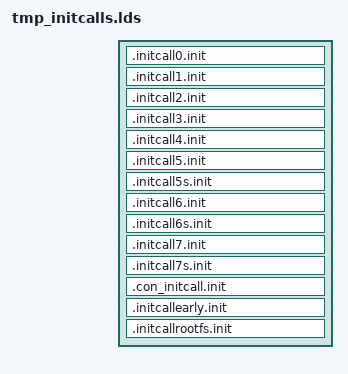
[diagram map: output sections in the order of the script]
SECTIONS {
	.initcall0.init : {
		*(.initcall0.init..kmod_shm__367_143_ipc_ns_init) ;
		*(.initcall0.init..kmod_min_addr__219_53_init_mmap_min_addr) ;
		*(.initcall0.init..kmod_pci__408_6605_pci_realloc_setup_params) ;
		*(.initcall0.init..kmod_net_namespace__576_1128_net_ns_init) ;
		*(.initcall0.init..kmod_inet_fragment__604_216_inet_frag_wq_init) ;
	}
	.initcall1.init : {
		*(.initcall1.init..kmod_e820__321_792_e820__register_nvs_regions) ;
		*(.initcall1.init..kmod_tsc__193_1028_cpufreq_register_tsc_scaling) ;
		*(.initcall1.init..kmod_reboot__355_516_reboot_init) ;
		*(.initcall1.init..kmod_apic__624_2779_init_lapic_sysfs) ;
		*(.initcall1.init..kmod_cpu__542_1454_alloc_frozen_cpus) ;
		*(.initcall1.init..kmod_cpu__544_1501_cpu_hotplug_pm_sync_init) ;
		*(.initcall1.init..kmod_workqueue__525_5640_wq_sysfs_init) ;
		*(.initcall1.init..kmod_ksysfs__238_269_ksysfs_init) ;
		*(.initcall1.init..kmod_cpufreq_schedutil__853_943_schedutil_gov_init) ;
		*(.initcall1.init..kmod_main__316_959_pm_init) ;
		*(.initcall1.init..kmod_hibernate__480_1268_pm_disk_init) ;
		*(.initcall1.init..kmod_swap__313_1613_swsusp_header_init) ;
		*(.initcall1.init..kmod_update__445_238_rcu_set_runtime_mode) ;
		*(.initcall1.init..kmod_jiffies__103_87_init_jiffies_clocksource) ;
		*(.initcall1.init..kmod_futex__327_4041_futex_init) ;
		*(.initcall1.init..kmod_cgroup__806_5785_cgroup_wq_init) ;
		*(.initcall1.init..kmod_cgroup_v1__351_1246_cgroup1_wq_init) ;
		*(.initcall1.init..kmod_trace_kprobe__313_1918_init_kprobe_trace_early) ;
		*(.initcall1.init..kmod_memory__426_157_init_zero_pfn) ;
		*(.initcall1.init..kmod_fsnotify__264_572_fsnotify_init) ;
		*(.initcall1.init..kmod_locks__467_3028_filelock_init) ;
		*(.initcall1.init..kmod_binfmt_misc__269_833_init_misc_binfmt) ;
		*(.initcall1.init..kmod_binfmt_script__197_156_init_script_binfmt) ;
		*(.initcall1.init..kmod_binfmt_elf__276_2311_init_elf_binfmt) ;
		*(.initcall1.init..kmod_compat_binfmt_elf__278_2311_init_compat_elf_binfmt) ;
		*(.initcall1.init..kmod_debugfs__266_844_debugfs_init) ;
		*(.initcall1.init..kmod_tracefs__244_550_tracefs_init) ;
		*(.initcall1.init..kmod_random32__417_489_prandom_init_early) ;
		*(.initcall1.init..kmod_iommu__392_2663_iommu_init) ;
		*(.initcall1.init..kmod_component__206_124_component_debug_init) ;
		*(.initcall1.init..kmod_trace__332_292_early_resume_init) ;
		*(.initcall1.init..kmod_cpufreq__559_2900_cpufreq_core_init) ;
		*(.initcall1.init..kmod_cpufreq_performance__180_44_cpufreq_gov_performance_init) ;
		*(.initcall1.init..kmod_cpufreq_userspace__183_141_cpufreq_gov_userspace_init) ;
		*(.initcall1.init..kmod_cpufreq_ondemand__195_477_CPU_FREQ_GOV_ONDEMAND_init) ;
		*(.initcall1.init..kmod_cpuidle__504_779_cpuidle_init) ;
		*(.initcall1.init..kmod_socket__637_3082_sock_init) ;
		*(.initcall1.init..kmod_sock__787_3384_net_inuse_init) ;
		*(.initcall1.init..kmod_net_namespace__545_393_net_defaults_init) ;
		*(.initcall1.init..kmod_flow_dissector__651_1806_init_default_flow_dissectors) ;
		*(.initcall1.init..kmod_netpoll__656_808_netpoll_init) ;
		*(.initcall1.init..kmod_af_netlink__647_2901_netlink_proto_init) ;
		*(.initcall1.init..kmod_genetlink__550_1411_genl_init) ;
		*(.initcall1.init..kmod_cpu__398_401_bsp_pm_check_init) ;
	}
	.initcall2.init : {
		*(.initcall2.init..kmod_irqdesc__172_331_irq_sysfs_init) ;
		*(.initcall2.init..kmod_audit__553_1677_audit_init) ;
		*(.initcall2.init..kmod_tracepoint__185_89_release_early_probes) ;
		*(.initcall2.init..kmod_backing_dev__511_231_bdi_class_init) ;
		*(.initcall2.init..kmod_mm_init__256_208_mm_sysfs_init) ;
		*(.initcall2.init..kmod_page_alloc__626_8038_init_per_zone_wmark_min) ;
		*(.initcall2.init..kmod_mpi__231_64_mpi_init) ;
		*(.initcall2.init..kmod_kobject_uevent__526_813_kobject_uevent_init) ;
		*(.initcall2.init..kmod_probe__249_108_pcibus_class_init) ;
		*(.initcall2.init..kmod_pci_driver__371_1660_pci_driver_init) ;
		*(.initcall2.init..kmod_backlight__281_770_backlight_class_init) ;
		*(.initcall2.init..kmod_tty_io__290_3448_tty_class_init) ;
		*(.initcall2.init..kmod_vt__301_4294_vtconsole_class_init) ;
		*(.initcall2.init..kmod_iommu_sysfs__228_47_iommu_dev_init) ;
		*(.initcall2.init..kmod_drm_mipi_dsi__300_1209_mipi_dsi_bus_init) ;
		*(.initcall2.init..kmod_core__373_563_devlink_class_init) ;
		*(.initcall2.init..kmod_swnode__203_896_software_node_init) ;
		*(.initcall2.init..kmod_wakeup__525_1187_wakeup_sources_debugfs_init) ;
		*(.initcall2.init..kmod_wakeup_stats__162_217_wakeup_sources_sysfs_init) ;
		*(.initcall2.init..kmod_node__310_1068_register_node_type) ;
		*(.initcall2.init..kmod_regmap__430_3301_regmap_initcall) ;
		*(.initcall2.init..kmod_i2c_core__396_1931_i2c_init) ;
		*(.initcall2.init..kmod_thermal_sys__400_1605_thermal_init) ;
		*(.initcall2.init..kmod_menu__155_574_init_menu) ;
		*(.initcall2.init..kmod_pcc__174_616_pcc_init) ;
		*(.initcall2.init..kmod_amd_bus__242_404_amd_postcore_init) ;
	}
	.initcall3.init : {
		*(.initcall3.init..kmod_bts__252_619_bts_init) ;
		*(.initcall3.init..kmod_pt__294_1761_pt_init) ;
		*(.initcall3.init..kmod_ksysfs__226_356_boot_params_ksysfs_init) ;
		*(.initcall3.init..kmod_bootflag__251_102_sbf_init) ;
		*(.initcall3.init..kmod_kdebugfs__222_176_arch_kdebugfs_init) ;
		*(.initcall3.init..kmod_intel_pconfig__10_82_intel_pconfig_init) ;
		*(.initcall3.init..kmod_if__194_424_mtrr_if_init) ;
		*(.initcall3.init..kmod_cstate__188_213_ffh_cstate_init) ;
		*(.initcall3.init..kmod_cryptomgr__340_288_cryptomgr_init) ;
		*(.initcall3.init..kmod_pci_acpi__263_1389_acpi_pci_init) ;
		*(.initcall3.init..kmod_dmaengine__253_293_dma_channel_table_init) ;
		*(.initcall3.init..kmod_dmaengine__329_1658_dma_bus_init) ;
		*(.initcall3.init..kmod_dma_iommu__284_1429_iommu_dma_init) ;
		*(.initcall3.init..kmod_dmi_id__166_254_dmi_id_init) ;
		*(.initcall3.init..kmod_init__234_51_pci_arch_init) ;
	}
	.initcall4.init : {
		*(.initcall4.init..kmod_vma__323_457_init_vdso) ;
		*(.initcall4.init..kmod_vdso32_setup__67_63_sysenter_setup) ;
		*(.initcall4.init..kmod_core__279_5656_fixup_ht_bug) ;
		*(.initcall4.init..kmod_topology__165_167_topology_init) ;
		*(.initcall4.init..kmod_intel_epb__159_216_intel_epb_init) ;
		*(.initcall4.init..kmod_mtrr__240_889_mtrr_init_finialize) ;
		*(.initcall4.init..kmod_user__144_229_uid_cache_init) ;
		*(.initcall4.init..kmod_params__295_956_param_sysfs_init) ;
		*(.initcall4.init..kmod_ucount__149_242_user_namespace_sysctl_init) ;
		*(.initcall4.init..kmod_stats__687_128_proc_schedstat_init) ;
		*(.initcall4.init..kmod_poweroff__69_45_pm_sysrq_init) ;
		*(.initcall4.init..kmod_profile__245_565_create_proc_profile) ;
		*(.initcall4.init..kmod_namespace__240_473_time_ns_init) ;
		*(.initcall4.init..kmod_crash_core__228_527_crash_save_vmcoreinfo_init) ;
		*(.initcall4.init..kmod_kexec_core__332_1117_crash_notes_memory_init) ;
		*(.initcall4.init..kmod_cgroup__820_6592_cgroup_sysfs_init) ;
		*(.initcall4.init..kmod_namespace__242_157_cgroup_namespaces_init) ;
		*(.initcall4.init..kmod_oom_kill__400_683_oom_init) ;
		*(.initcall4.init..kmod_backing_dev__513_248_default_bdi_init) ;
		*(.initcall4.init..kmod_percpu__425_3181_percpu_enable_async) ;
		*(.initcall4.init..kmod_compaction__478_2966_kcompactd_init) ;
		*(.initcall4.init..kmod_mmap__417_3764_init_user_reserve) ;
		*(.initcall4.init..kmod_mmap__421_3785_init_admin_reserve) ;
		*(.initcall4.init..kmod_mmap__423_3855_init_reserve_notifier) ;
		*(.initcall4.init..kmod_swap_state__323_955_swap_init_sysfs) ;
		*(.initcall4.init..kmod_swapfile__420_3843_swapfile_init) ;
		*(.initcall4.init..kmod_hugetlb__364_3222_hugetlb_init) ;
		*(.initcall4.init..kmod_io_wq__715_1211_io_wq_init) ;
		*(.initcall4.init..kmod_seqiv__254_183_seqiv_module_init) ;
		*(.initcall4.init..kmod_echainiv__254_160_echainiv_module_init) ;
		*(.initcall4.init..kmod_rsa_generic__238_281_rsa_init) ;
		*(.initcall4.init..kmod_cmac__111_310_crypto_cmac_module_init) ;
		*(.initcall4.init..kmod_hmac__250_254_hmac_module_init) ;
		*(.initcall4.init..kmod_crypto_null__254_221_crypto_null_mod_init) ;
		*(.initcall4.init..kmod_md5__112_245_md5_mod_init) ;
		*(.initcall4.init..kmod_sha256_generic__244_113_sha256_generic_mod_init) ;
		*(.initcall4.init..kmod_cbc__109_217_crypto_cbc_module_init) ;
		*(.initcall4.init..kmod_ctr__112_354_crypto_ctr_module_init) ;
		*(.initcall4.init..kmod_gcm__266_1159_crypto_gcm_module_init) ;
		*(.initcall4.init..kmod_ccm__268_948_crypto_ccm_module_init) ;
		*(.initcall4.init..kmod_aes_generic__104_1314_aes_init) ;
		*(.initcall4.init..kmod_crc32c_generic__111_161_crc32c_mod_init) ;
		*(.initcall4.init..kmod_authenc__366_464_crypto_authenc_module_init) ;
		*(.initcall4.init..kmod_authencesn__364_479_crypto_authenc_esn_module_init) ;
		*(.initcall4.init..kmod_drbg__272_2145_drbg_init) ;
		*(.initcall4.init..kmod_ghash_generic__114_178_ghash_mod_init) ;
		*(.initcall4.init..kmod_bio__510_1675_init_bio) ;
		*(.initcall4.init..kmod_blk_settings__406_888_blk_settings_init) ;
		*(.initcall4.init..kmod_blk_ioc__305_422_blk_ioc_init) ;
		*(.initcall4.init..kmod_blk_mq__555_3920_blk_mq_init) ;
		*(.initcall4.init..kmod_genhd__337_1104_genhd_device_init) ;
		*(.initcall4.init..kmod_slot__259_380_pci_slot_init) ;
		*(.initcall4.init..kmod_fb__317_1934_fbmem_init) ;
		*(.initcall4.init..kmod_acpi__337_1264_acpi_init) ;
		*(.initcall4.init..kmod_pnp__241_247_pnp_init) ;
		*(.initcall4.init..kmod_misc__219_291_misc_init) ;
		*(.initcall4.init..kmod_iommu__288_153_iommu_subsys_init) ;
		*(.initcall4.init..kmod_vgaarb__262_1567_vga_arb_device_init) ;
		*(.initcall4.init..kmod_cn__534_283_cn_init) ;
		*(.initcall4.init..kmod_dma_buf__296_1424_dma_buf_init) ;
		*(.initcall4.init..kmod_scsi_mod__383_804_init_scsi) ;
		*(.initcall4.init..kmod_libata__493_6313_ata_init) ;
		*(.initcall4.init..kmod_libphy__462_3092_phy_init) ;
		*(.initcall4.init..kmod_pcmcia_core__271_918_init_pcmcia_cs) ;
		*(.initcall4.init..kmod_usb_common__309_312_usb_common_init) ;
		*(.initcall4.init..kmod_usbcore__345_1043_usb_init) ;
		*(.initcall4.init..kmod_serio__223_1052_serio_init) ;
		*(.initcall4.init..kmod_input_core__360_2634_input_init) ;
		*(.initcall4.init..kmod_rtc_core__248_469_rtc_init) ;
		*(.initcall4.init..kmod_pps_core__211_484_pps_init) ;
		*(.initcall4.init..kmod_ptp__266_433_ptp_init) ;
		*(.initcall4.init..kmod_power_supply__198_1380_power_supply_class_init) ;
		*(.initcall4.init..kmod_hwmon__299_1035_hwmon_init) ;
		*(.initcall4.init..kmod_md_mod__704_9868_md_init) ;
		*(.initcall4.init..kmod_led_class__176_544_leds_init) ;
		*(.initcall4.init..kmod_dmi_scan__269_803_dmi_init) ;
		*(.initcall4.init..kmod_efi__286_436_efisubsys_init) ;
		*(.initcall4.init..kmod_nvmem_core__296_1806_nvmem_init) ;
		*(.initcall4.init..kmod_soundcore__168_65_init_soundcore) ;
		*(.initcall4.init..kmod_snd__230_410_alsa_sound_init) ;
		*(.initcall4.init..kmod_snd_seq_device__226_302_alsa_seq_device_init) ;
		*(.initcall4.init..kmod_snd_hda_core__239_96_hda_bus_init) ;
		*(.initcall4.init..kmod_sock__794_3684_proto_init) ;
		*(.initcall4.init..kmod_dev__1472_11315_net_dev_init) ;
		*(.initcall4.init..kmod_neighbour__709_3736_neigh_init) ;
		*(.initcall4.init..kmod_fib_notifier__348_199_fib_notifier_init) ;
		*(.initcall4.init..kmod_fib_rules__654_1298_fib_rules_init) ;
		*(.initcall4.init..kmod_sch_api__610_2304_pktsched_init) ;
		*(.initcall4.init..kmod_cls_api__719_3907_tc_filter_init) ;
		*(.initcall4.init..kmod_act_api__564_1668_tc_action_init) ;
		*(.initcall4.init..kmod_ethtool_nl__535_948_ethnl_init) ;
		*(.initcall4.init..kmod_nexthop__668_2254_nexthop_init) ;
		*(.initcall4.init..kmod_cipso_ipv4__618_2302_cipso_v4_init) ;
		*(.initcall4.init..kmod_mac80211__1779_1454_ieee80211_init) ;
		*(.initcall4.init..kmod_netlabel_kapi__575_1523_netlbl_init) ;
		*(.initcall4.init..kmod_rfkill__287_1397_rfkill_init) ;
		*(.initcall4.init..kmod_legacy__235_77_pci_subsys_init) ;
	}
	.initcall5.init : {
		*(.initcall5.init..kmod_nmi__330_102_nmi_warning_debugfs) ;
		*(.initcall5.init..kmod_microcode__230_908_save_microcode_in_initrd) ;
		*(.initcall5.init..kmod_hpet__174_1084_hpet_late_init) ;
		*(.initcall5.init..kmod_amd_nb__243_541_init_amd_nbs) ;
		*(.initcall5.init..kmod_clocksource__188_819_clocksource_done_booting) ;
		*(.initcall5.init..kmod_trace__396_9685_tracer_init_tracefs) ;
		*(.initcall5.init..kmod_trace_printk__266_382_init_trace_printk_function_export) ;
		*(.initcall5.init..kmod_trace_kprobe__315_1948_init_kprobe_trace) ;
		*(.initcall5.init..kmod_trace_dynevent__266_225_init_dynamic_event) ;
		*(.initcall5.init..kmod_trace_uprobe__322_1659_init_uprobe_trace) ;
		*(.initcall5.init..kmod_pipe__327_1431_init_pipe_fs) ;
		*(.initcall5.init..kmod_inotify_user__346_851_inotify_user_setup) ;
		*(.initcall5.init..kmod_eventpoll__625_2380_eventpoll_init) ;
		*(.initcall5.init..kmod_anon_inodes__232_164_anon_inode_init) ;
		*(.initcall5.init..kmod_locks__465_3005_proc_locks_init) ;
		*(.initcall5.init..kmod_iomap__435_1578_iomap_init) ;
		*(.initcall5.init..kmod_dquot__358_2990_dquot_init) ;
		*(.initcall5.init..kmod_netlink__288_103_quota_init) ;
		*(.initcall5.init..kmod_proc__188_19_proc_cmdline_init) ;
		*(.initcall5.init..kmod_proc__204_98_proc_consoles_init) ;
		*(.initcall5.init..kmod_proc__217_32_proc_cpuinfo_init) ;
		*(.initcall5.init..kmod_proc__281_60_proc_devices_init) ;
		*(.initcall5.init..kmod_proc__188_42_proc_interrupts_init) ;
		*(.initcall5.init..kmod_proc__222_33_proc_loadavg_init) ;
		*(.initcall5.init..kmod_proc__297_161_proc_meminfo_init) ;
		*(.initcall5.init..kmod_proc__203_242_proc_stat_init) ;
		*(.initcall5.init..kmod_proc__188_41_proc_uptime_init) ;
		*(.initcall5.init..kmod_proc__188_23_proc_version_init) ;
		*(.initcall5.init..kmod_proc__188_33_proc_softirqs_init) ;
		*(.initcall5.init..kmod_proc__263_656_proc_kcore_init) ;
		*(.initcall5.init..kmod_proc__271_1563_vmcore_init) ;
		*(.initcall5.init..kmod_proc__186_66_proc_kmsg_init) ;
		*(.initcall5.init..kmod_proc__303_338_proc_page_init) ;
		*(.initcall5.init..kmod_ramfs__291_285_init_ramfs_fs) ;
		*(.initcall5.init..kmod_hugetlbfs__301_1590_init_hugetlbfs_fs) ;
		*(.initcall5.init..kmod_scsi_ioctl__312_891_blk_scsi_ioctl_init) ;
		*(.initcall5.init..kmod_acpi__298_181_acpi_event_init) ;
		*(.initcall5.init..kmod_pnp__161_113_pnp_system_init) ;
		*(.initcall5.init..kmod_pnp__183_314_pnpacpi_init) ;
		*(.initcall5.init..kmod_mem__314_1100_chr_dev_init) ;
		*(.initcall5.init..kmod_firmware_class__320_1572_firmware_class_init) ;
		*(.initcall5.init..kmod_pcmcia__288_1444_init_pcmcia_bus) ;
		*(.initcall5.init..kmod_acpi_pm__240_220_init_acpi_pm_clocksource) ;
		*(.initcall5.init..kmod_sysctl_net_core__577_655_sysctl_core_init) ;
		*(.initcall5.init..kmod_eth__590_500_eth_offload_init) ;
		*(.initcall5.init..kmod_af_inet__720_1930_ipv4_offload_init) ;
		*(.initcall5.init..kmod_af_inet__723_2063_inet_init) ;
		*(.initcall5.init..kmod_unix__569_2937_af_unix_init) ;
		*(.initcall5.init..kmod_ip6_offload__602_445_ipv6_offload_init) ;
		*(.initcall5.init..kmod_sunrpc__548_142_init_sunrpc) ;
		*(.initcall5.init..kmod_cfg80211__1716_1521_cfg80211_init) ;
		*(.initcall5.init..kmod_i386__248_373_pcibios_assign_resources) ;
	}
	.initcall5s.init : {
		*(.initcall5s.init..kmod_quirks__244_193_pci_apply_final_quirks) ;
		*(.initcall5s.init..kmod_acpi__285_139_acpi_reserve_resources) ;
	}
	.initcall6.init : {
		*(.initcall6.init..kmod_vdso32_setup__69_96_ia32_binfmt_init) ;
		*(.initcall6.init..kmod_rapl__255_859_rapl_pmu_init) ;
		*(.initcall6.init..kmod_uncore__257_670_amd_uncore_init) ;
		*(.initcall6.init..kmod_ibs__272_1069_amd_ibs_init) ;
		*(.initcall6.init..kmod_iommu__258_483_amd_iommu_pc_init) ;
		*(.initcall6.init..kmod_msr__247_306_msr_init) ;
		*(.initcall6.init..kmod_intel_uncore__290_1748_intel_uncore_init) ;
		*(.initcall6.init..kmod_intel_cstate__252_747_cstate_pmu_init) ;
		*(.initcall6.init..kmod_setup__375_1267_register_kernel_offset_dumper) ;
		*(.initcall6.init..kmod_i8259__199_434_i8259A_init_ops) ;
		*(.initcall6.init..kmod_tsc__198_1413_init_tsc_clocksource) ;
		*(.initcall6.init..kmod_rtc__286_207_add_rtc_cmos) ;
		*(.initcall6.init..kmod_i8237__95_76_i8237A_init_ops) ;
		*(.initcall6.init..kmod_umwait__300_238_umwait_init) ;
		*(.initcall6.init..kmod_therm_throt__564_517_thermal_throttle_init_device) ;
		*(.initcall6.init..kmod_msr__231_279_msr_init) ;
		*(.initcall6.init..kmod_cpuid__206_178_cpuid_init) ;
		*(.initcall6.init..kmod_io_apic__313_2450_ioapic_init_ops) ;
		*(.initcall6.init..kmod_pcspeaker__159_14_add_pcspkr) ;
		*(.initcall6.init..kmod_check__227_186_start_periodic_check_for_corruption) ;
		*(.initcall6.init..kmod_sysfb__252_70_sysfb_init) ;
		*(.initcall6.init..kmod_audit_64__224_83_audit_classes_init) ;
		*(.initcall6.init..kmod_iosf_mbi__258_566_iosf_mbi_init) ;
		*(.initcall6.init..kmod_exec_domain__252_35_proc_execdomains_init) ;
		*(.initcall6.init..kmod_panic__262_675_register_warn_debugfs) ;
		*(.initcall6.init..kmod_cpu__557_2408_cpuhp_sysfs_init) ;
		*(.initcall6.init..kmod_resource__233_146_ioresources_init) ;
		*(.initcall6.init..kmod_user__301_451_snapshot_device_init) ;
		*(.initcall6.init..kmod_pm__300_249_irq_pm_init_ops) ;
		*(.initcall6.init..kmod_timekeeping__267_1886_timekeeping_init_ops) ;
		*(.initcall6.init..kmod_clocksource__205_1198_init_clocksource_sysfs) ;
		*(.initcall6.init..kmod_timer_list__235_351_init_timer_list_procfs) ;
		*(.initcall6.init..kmod_alarmtimer__332_933_alarmtimer_init) ;
		*(.initcall6.init..kmod_posix_timers__258_280_init_posix_timers) ;
		*(.initcall6.init..kmod_clockevents__198_777_clockevents_init_sysfs) ;
		*(.initcall6.init..kmod_dma__188_144_proc_dma_init) ;
		*(.initcall6.init..kmod_module__398_4530_proc_modules_init) ;
		*(.initcall6.init..kmod_kallsyms__395_751_kallsyms_init) ;
		*(.initcall6.init..kmod_pid_namespace__257_460_pid_namespaces_init) ;
		*(.initcall6.init..kmod_audit_watch__306_503_audit_watch_init) ;
		*(.initcall6.init..kmod_audit_fsnotify__286_192_audit_fsnotify_init) ;
		*(.initcall6.init..kmod_audit_tree__315_1089_audit_tree_init) ;
		*(.initcall6.init..kmod_seccomp__484_2337_seccomp_sysctl_init) ;
		*(.initcall6.init..kmod_utsname_sysctl__127_144_utsname_sysctl_init) ;
		*(.initcall6.init..kmod_tracepoint__212_569_init_tracepoints) ;
		*(.initcall6.init..kmod_blktrace__480_1598_init_blk_tracer) ;
		*(.initcall6.init..kmod_core__775_13134_perf_event_sysfs_init) ;
		*(.initcall6.init..kmod_system_keyring__143_132_system_trusted_keyring_init) ;
		*(.initcall6.init..kmod_vmscan__493_4087_kswapd_init) ;
		*(.initcall6.init..kmod_vmstat__325_2181_extfrag_debug_init) ;
		*(.initcall6.init..kmod_mm_init__254_196_mm_compute_batch_init) ;
		*(.initcall6.init..kmod_slab_common__440_1064_slab_proc_init) ;
		*(.initcall6.init..kmod_workingset__303_627_workingset_init) ;
		*(.initcall6.init..kmod_vmalloc__414_3594_proc_vmalloc_init) ;
		*(.initcall6.init..kmod_swapfile__375_2853_procswaps_init) ;
		*(.initcall6.init..kmod_slub__492_5748_slab_sysfs_init) ;
		*(.initcall6.init..kmod_fcntl__283_1048_fcntl_init) ;
		*(.initcall6.init..kmod_filesystems__255_251_proc_filesystems_init) ;
		*(.initcall6.init..kmod_fs_writeback__584_2186_start_dirtytime_writeback) ;
		*(.initcall6.init..kmod_block_dev__314_505_blkdev_init) ;
		*(.initcall6.init..kmod_direct_io__298_1376_dio_init) ;
		*(.initcall6.init..kmod_dnotify__242_392_dnotify_init) ;
		*(.initcall6.init..kmod_aio__308_279_aio_setup) ;
		*(.initcall6.init..kmod_io_uring__943_10204_io_uring_init) ;
		*(.initcall6.init..kmod_mbcache__222_432_mbcache_init) ;
		*(.initcall6.init..kmod_grace__297_142_init_grace) ;
		*(.initcall6.init..kmod_quota_v2__205_431_init_v2_quota_format) ;
		*(.initcall6.init..kmod_devpts__243_637_init_devpts_fs) ;
		*(.initcall6.init..kmod_ext4__1430_6763_ext4_init_fs) ;
		*(.initcall6.init..kmod_jbd2__539_3011_journal_init) ;
		*(.initcall6.init..kmod_fat__316_1978_init_fat_fs) ;
		*(.initcall6.init..kmod_vfat__251_1083_init_vfat_fs) ;
		*(.initcall6.init..kmod_msdos__247_686_init_msdos_fs) ;
		*(.initcall6.init..kmod_isofs__288_1611_init_iso9660_fs) ;
		*(.initcall6.init..kmod_nfs__1011_2319_init_nfs_fs) ;
		*(.initcall6.init..kmod_nfsv2__552_31_init_nfs_v2) ;
		*(.initcall6.init..kmod_nfsv3__552_35_init_nfs_v3) ;
		*(.initcall6.init..kmod_nfsv4__554_313_init_nfs_v4) ;
		*(.initcall6.init..kmod_lockd__577_766_init_nlm) ;
		*(.initcall6.init..kmod_nls_cp437__99_384_init_nls_cp437) ;
		*(.initcall6.init..kmod_nls_ascii__99_163_init_nls_ascii) ;
		*(.initcall6.init..kmod_nls_iso8859_1__99_254_init_nls_iso8859_1) ;
		*(.initcall6.init..kmod_nls_utf8__99_65_init_nls_utf8) ;
		*(.initcall6.init..kmod_autofs4__203_44_init_autofs_fs) ;
		*(.initcall6.init..kmod_util__286_98_ipc_init) ;
		*(.initcall6.init..kmod_ipc_sysctl__200_243_ipc_sysctl_init) ;
		*(.initcall6.init..kmod_mqueue__559_1735_init_mqueue_fs) ;
		*(.initcall6.init..kmod_proc__222_58_key_proc_init) ;
		*(.initcall6.init..kmod_selinux__677_7376_selinux_nf_ip_init) ;
		*(.initcall6.init..kmod_selinux__593_2246_init_sel_fs) ;
		*(.initcall6.init..kmod_selinux__301_121_selnl_init) ;
		*(.initcall6.init..kmod_selinux__594_280_sel_netif_init) ;
		*(.initcall6.init..kmod_selinux__600_305_sel_netnode_init) ;
		*(.initcall6.init..kmod_selinux__597_239_sel_netport_init) ;
		*(.initcall6.init..kmod_selinux__652_3717_aurule_init) ;
		*(.initcall6.init..kmod_crypto_algapi__405_1293_crypto_algapi_init) ;
		*(.initcall6.init..kmod_jitterentropy_rng__104_217_jent_mod_init) ;
		*(.initcall6.init..kmod_asymmetric_keys__219_651_asymmetric_key_init) ;
		*(.initcall6.init..kmod_x509_key_parser__207_268_x509_key_init) ;
		*(.initcall6.init..kmod_genhd__364_1536_proc_genhd_init) ;
		*(.initcall6.init..kmod_bsg__304_520_bsg_init) ;
		*(.initcall6.init..kmod_mq_deadline__307_818_deadline_init) ;
		*(.initcall6.init..kmod_kyber_iosched__376_1045_kyber_init) ;
		*(.initcall6.init..kmod_percpu_counter__178_257_percpu_counter_startup) ;
		*(.initcall6.init..kmod_sg_pool__235_190_sg_pool_init) ;
		*(.initcall6.init..kmod_pcieportdrv__239_271_pcie_portdrv_init) ;
		*(.initcall6.init..kmod_proc__240_462_pci_proc_init) ;
		*(.initcall6.init..kmod_pci_hotplug__266_573_pci_hotplug_init) ;
		*(.initcall6.init..kmod_efifb__373_616_efifb_driver_init) ;
		*(.initcall6.init..kmod_acpi__177_196_ged_driver_init) ;
		*(.initcall6.init..kmod_ac__178_369_acpi_ac_init) ;
		*(.initcall6.init..kmod_button__228_658_acpi_button_driver_init) ;
		*(.initcall6.init..kmod_fan__185_497_acpi_fan_driver_init) ;
		*(.initcall6.init..kmod_video__359_2299_acpi_video_init) ;
		*(.initcall6.init..kmod_processor__192_364_acpi_processor_driver_init) ;
		*(.initcall6.init..kmod_thermal__194_1254_acpi_thermal_init) ;
		*(.initcall6.init..kmod_battery__322_1314_acpi_battery_init) ;
		*(.initcall6.init..kmod_bgrt__172_122_bgrt_init) ;
		*(.initcall6.init..kmod_clk_gpio__203_249_gpio_clk_driver_init) ;
		*(.initcall6.init..kmod_clk_pmc_atom__166_390_plt_clk_driver_init) ;
		*(.initcall6.init..kmod_n_null__209_62_n_null_init) ;
		*(.initcall6.init..kmod_pty__237_970_pty_init) ;
		*(.initcall6.init..kmod_sysrq__321_1192_sysrq_init) ;
		*(.initcall6.init..kmod_8250__296_1246_serial8250_init) ;
		*(.initcall6.init..kmod_8250_pci__285_5723_serial_pci_driver_init) ;
		*(.initcall6.init..kmod_8250_exar__284_853_exar_pci_driver_init) ;
		*(.initcall6.init..kmod_8250_lpss__283_399_lpss8250_pci_driver_init) ;
		*(.initcall6.init..kmod_8250_mid__282_391_mid8250_pci_driver_init) ;
		*(.initcall6.init..kmod_hpet__243_1074_hpet_init) ;
		*(.initcall6.init..kmod_nvram__288_540_nvram_module_init) ;
		*(.initcall6.init..kmod_rng_core__235_647_hwrng_modinit) ;
		*(.initcall6.init..kmod_via_rng__99_212_mod_init) ;
		*(.initcall6.init..kmod_agpgart__266_364_agp_init) ;
		*(.initcall6.init..kmod_amd64_agp__240_814_agp_amd64_mod_init) ;
		*(.initcall6.init..kmod_intel_agp__258_920_agp_intel_init) ;
		*(.initcall6.init..kmod_drm_kms_helper__269_88_drm_kms_helper_init) ;
		*(.initcall6.init..kmod_drm__286_1075_drm_core_init) ;
		*(.initcall6.init..kmod_i915__441_1177_i915_init) ;
		*(.initcall6.init..kmod_cn_proc__529_403_cn_proc_init) ;
		*(.initcall6.init..kmod_topology__230_143_topology_sysfs_init) ;
		*(.initcall6.init..kmod_cacheinfo__172_674_cacheinfo_sysfs_init) ;
		*(.initcall6.init..kmod_loop__337_2395_loop_init) ;
		*(.initcall6.init..kmod_mac_hid__211_274_mac_hid_init) ;
		*(.initcall6.init..kmod_scsi_transport_spi__402_1639_spi_transport_init) ;
		*(.initcall6.init..kmod_sd_mod__383_3794_init_sd) ;
		*(.initcall6.init..kmod_sr_mod__308_1071_init_sr) ;
		*(.initcall6.init..kmod_sg__345_2637_init_sg) ;
		*(.initcall6.init..kmod_ahci__330_1928_ahci_pci_driver_init) ;
		*(.initcall6.init..kmod_ata_piix__318_1786_piix_init) ;
		*(.initcall6.init..kmod_pata_amd__342_636_amd_pci_driver_init) ;
		*(.initcall6.init..kmod_pata_oldpiix__303_268_oldpiix_pci_driver_init) ;
		*(.initcall6.init..kmod_pata_sch__307_167_sch_pci_driver_init) ;
		*(.initcall6.init..kmod_Space__332_155_net_olddevs_init) ;
		*(.initcall6.init..kmod_loopback__534_277_blackhole_netdev_init) ;
		*(.initcall6.init..kmod_realtek__280_829_phy_module_init) ;
		*(.initcall6.init..kmod_tg3__645_18328_tg3_driver_init) ;
		*(.initcall6.init..kmod_e100__373_3173_e100_init_module) ;
		*(.initcall6.init..kmod_e1000__567_238_e1000_init_module) ;
		*(.initcall6.init..kmod_e1000e__600_7891_e1000_init_module) ;
		*(.initcall6.init..kmod_sky2__582_5291_sky2_init_module) ;
		*(.initcall6.init..kmod_forcedeth__369_6493_forcedeth_pci_driver_init) ;
		*(.initcall6.init..kmod_8139too__366_2676_rtl8139_init_module) ;
		*(.initcall6.init..kmod_r8169__646_5462_rtl8169_pci_driver_init) ;
		*(.initcall6.init..kmod_cdrom__325_3776_cdrom_init) ;
		*(.initcall6.init..kmod_pcmcia_rsrc__242_1233_nonstatic_sysfs_init) ;
		*(.initcall6.init..kmod_yenta_socket__269_1456_yenta_cardbus_driver_init) ;
		*(.initcall6.init..kmod_usbmon__225_432_mon_init) ;
		*(.initcall6.init..kmod_ehci_hcd__393_1373_ehci_hcd_init) ;
		*(.initcall6.init..kmod_ehci_pci__250_420_ehci_pci_init) ;
		*(.initcall6.init..kmod_ohci_hcd__359_1347_ohci_hcd_mod_init) ;
		*(.initcall6.init..kmod_ohci_pci__251_321_ohci_pci_init) ;
		*(.initcall6.init..kmod_uhci_hcd__349_940_uhci_hcd_init) ;
		*(.initcall6.init..kmod_xhci_hcd__663_5562_xhci_hcd_init) ;
		*(.initcall6.init..kmod_xhci_pci__631_650_xhci_pci_init) ;
		*(.initcall6.init..kmod_usblp__218_1460_usblp_driver_init) ;
		*(.initcall6.init..kmod_usb_storage__326_1159_usb_storage_driver_init) ;
		*(.initcall6.init..kmod_i8042__332_1658_i8042_init) ;
		*(.initcall6.init..kmod_serport__217_306_serport_init) ;
		*(.initcall6.init..kmod_input_leds__211_209_input_leds_init) ;
		*(.initcall6.init..kmod_evdev__258_1441_evdev_init) ;
		*(.initcall6.init..kmod_atkbd__232_1913_atkbd_init) ;
		*(.initcall6.init..kmod_psmouse__233_2087_psmouse_init) ;
		*(.initcall6.init..kmod_rtc_cmos__255_1493_cmos_init) ;
		*(.initcall6.init..kmod_i2c_smbus__178_198_smbalert_driver_init) ;
		*(.initcall6.init..kmod_i2c_i801__253_2014_i2c_i801_init) ;
		*(.initcall6.init..kmod_dm_mod__501_3088_dm_init) ;
		*(.initcall6.init..kmod_dm_mirror__290_1492_dm_mirror_init) ;
		*(.initcall6.init..kmod_dm_log__289_885_dm_dirty_log_init) ;
		*(.initcall6.init..kmod_dm_zero__283_83_dm_zero_init) ;
		*(.initcall6.init..kmod_intel_pstate__497_3149_intel_pstate_init) ;
		*(.initcall6.init..kmod_efivars__256_669_efivars_sysfs_init) ;
		*(.initcall6.init..kmod_esrt__268_432_esrt_sysfs_init) ;
		*(.initcall6.init..kmod_hid__297_2626_hid_init) ;
		*(.initcall6.init..kmod_hid_generic__210_82_hid_generic_init) ;
		*(.initcall6.init..kmod_hid_a4tech__209_162_a4_driver_init) ;
		*(.initcall6.init..kmod_hid_apple__217_635_apple_driver_init) ;
		*(.initcall6.init..kmod_hid_belkin__209_86_belkin_driver_init) ;
		*(.initcall6.init..kmod_hid_cherry__209_69_ch_driver_init) ;
		*(.initcall6.init..kmod_hid_chicony__218_95_ch_driver_init) ;
		*(.initcall6.init..kmod_hid_cypress__209_177_cp_driver_init) ;
		*(.initcall6.init..kmod_hid_ezkey__209_76_ez_driver_init) ;
		*(.initcall6.init..kmod_hid_gyration__209_88_gyration_driver_init) ;
		*(.initcall6.init..kmod_hid_ite__209_130_ite_driver_init) ;
		*(.initcall6.init..kmod_hid_kensington__209_47_ks_driver_init) ;
		*(.initcall6.init..kmod_hid_logitech__220_955_lg_driver_init) ;
		*(.initcall6.init..kmod_hid_lg_g15__235_903_lg_g15_driver_init) ;
		*(.initcall6.init..kmod_hid_microsoft__211_467_ms_driver_init) ;
		*(.initcall6.init..kmod_hid_monterey__209_63_mr_driver_init) ;
		*(.initcall6.init..kmod_hid_ntrig__246_1030_ntrig_driver_init) ;
		*(.initcall6.init..kmod_hid_pl__212_220_pl_driver_init) ;
		*(.initcall6.init..kmod_hid_petalynx__209_103_pl_driver_init) ;
		*(.initcall6.init..kmod_hid_redragon__209_60_redragon_driver_init) ;
		*(.initcall6.init..kmod_hid_samsung__218_194_samsung_driver_init) ;
		*(.initcall6.init..kmod_hid_sony__242_3207_sony_init) ;
		*(.initcall6.init..kmod_hid_sunplus__209_63_sp_driver_init) ;
		*(.initcall6.init..kmod_hid_topseed__209_79_ts_driver_init) ;
		*(.initcall6.init..kmod_usbhid__283_1695_hid_init) ;
		*(.initcall6.init..kmod_eeepc_laptop__272_1510_eeepc_laptop_init) ;
		*(.initcall6.init..kmod_pmc_atom__238_556_pmc_atom_init) ;
		*(.initcall6.init..kmod_snd_hwdep__226_542_alsa_hwdep_init) ;
		*(.initcall6.init..kmod_snd_timer__287_2346_alsa_timer_init) ;
		*(.initcall6.init..kmod_snd_hrtimer__171_168_snd_hrtimer_init) ;
		*(.initcall6.init..kmod_snd_pcm__257_1231_alsa_pcm_init) ;
		*(.initcall6.init..kmod_snd_seq__228_119_alsa_seq_init) ;
		*(.initcall6.init..kmod_snd_seq_dummy__217_211_alsa_seq_dummy_init) ;
		*(.initcall6.init..kmod_snd_hda_intel__374_2788_azx_driver_init) ;
		*(.initcall6.init..kmod_sock_diag__547_339_sock_diag_init) ;
		*(.initcall6.init..kmod_sch_blackhole__369_41_blackhole_init) ;
		*(.initcall6.init..kmod_nfnetlink__552_675_nfnetlink_init) ;
		*(.initcall6.init..kmod_nfnetlink_log__572_1202_nfnetlink_log_init) ;
		*(.initcall6.init..kmod_nf_conntrack__603_1213_nf_conntrack_standalone_init) ;
		*(.initcall6.init..kmod_nf_conntrack_netlink__616_3952_ctnetlink_init) ;
		*(.initcall6.init..kmod_nf_conntrack_ftp__653_610_nf_conntrack_ftp_init) ;
		*(.initcall6.init..kmod_nf_conntrack_irc__607_281_nf_conntrack_irc_init) ;
		*(.initcall6.init..kmod_nf_conntrack_sip__678_1701_nf_conntrack_sip_init) ;
		*(.initcall6.init..kmod_nf_nat__633_1206_nf_nat_init) ;
		*(.initcall6.init..kmod_nf_nat_ftp__600_150_nf_nat_ftp_init) ;
		*(.initcall6.init..kmod_nf_nat_irc__600_121_nf_nat_irc_init) ;
		*(.initcall6.init..kmod_nf_nat_sip__603_687_nf_nat_sip_init) ;
		*(.initcall6.init..kmod_x_tables__700_1900_xt_init) ;
		*(.initcall6.init..kmod_xt_tcpudp__615_231_tcpudp_mt_init) ;
		*(.initcall6.init..kmod_xt_CONNSECMARK__599_138_connsecmark_tg_init) ;
		*(.initcall6.init..kmod_xt_NFLOG__342_80_nflog_tg_init) ;
		*(.initcall6.init..kmod_xt_SECMARK__343_140_secmark_tg_init) ;
		*(.initcall6.init..kmod_xt_TCPMSS__616_344_tcpmss_tg_init) ;
		*(.initcall6.init..kmod_xt_conntrack__599_326_conntrack_mt_init) ;
		*(.initcall6.init..kmod_xt_policy__575_186_policy_mt_init) ;
		*(.initcall6.init..kmod_xt_state__598_74_state_mt_init) ;
		*(.initcall6.init..kmod_gre_offload__584_290_gre_offload_init) ;
		*(.initcall6.init..kmod_sysctl_net_ipv4__608_1427_sysctl_ipv4_init) ;
		*(.initcall6.init..kmod_tunnel4__576_298_tunnel4_init) ;
		*(.initcall6.init..kmod_nf_defrag_ipv4__601_154_nf_defrag_init) ;
		*(.initcall6.init..kmod_ip_tables__577_1929_ip_tables_init) ;
		*(.initcall6.init..kmod_iptable_filter__566_117_iptable_filter_init) ;
		*(.initcall6.init..kmod_iptable_mangle__565_154_iptable_mangle_init) ;
		*(.initcall6.init..kmod_ipt_REJECT__565_110_reject_tg_init) ;
		*(.initcall6.init..kmod_tcp_cubic__622_534_cubictcp_register) ;
		*(.initcall6.init..kmod_xfrm_user__586_3519_xfrm_user_init) ;
		*(.initcall6.init..kmod_ipv6__673_1280_inet6_init) ;
		*(.initcall6.init..kmod_ah6__600_801_ah6_init) ;
		*(.initcall6.init..kmod_esp6__655_1287_esp6_init) ;
		*(.initcall6.init..kmod_ip6_tables__620_1941_ip6_tables_init) ;
		*(.initcall6.init..kmod_ip6table_filter__609_118_ip6table_filter_init) ;
		*(.initcall6.init..kmod_ip6table_mangle__608_145_ip6table_mangle_init) ;
		*(.initcall6.init..kmod_nf_defrag_ipv6__642_155_nf_defrag_init) ;
		*(.initcall6.init..kmod_ip6t_ipv6header__608_152_ipv6header_mt6_init) ;
		*(.initcall6.init..kmod_ip6t_REJECT__608_120_reject_tg6_init) ;
		*(.initcall6.init..kmod_sit__643_2015_sit_init) ;
		*(.initcall6.init..kmod_af_packet__631_4692_packet_init) ;
		*(.initcall6.init..kmod_auth_rpcgss__793_2262_init_rpcsec_gss) ;
		*(.initcall6.init..kmod_dns_resolver__208_382_init_dns_resolver) ;
		*(.initcall6.init..kmod_cpu__400_514_pm_check_save_msr) ;
	}
	.initcall6s.init : {
		*(.initcall6s.init..kmod_core__357_2686_mcheck_init_device) ;
	}
	.initcall7.init : {
		*(.initcall7.init..kmod_core__359_2761_mcheck_late_init) ;
		*(.initcall7.init..kmod_severity__322_491_severities_debugfs_init) ;
		*(.initcall7.init..kmod_microcode__232_909_microcode_init) ;
		*(.initcall7.init..kmod_boot__307_949_hpet_insert_resource) ;
		*(.initcall7.init..kmod_mpparse__282_944_update_mp_table) ;
		*(.initcall7.init..kmod_apic__626_2919_lapic_insert_resource) ;
		*(.initcall7.init..kmod_ipi__69_27_print_ipi_mode) ;
		*(.initcall7.init..kmod_vector__582_1307_print_ICs) ;
		*(.initcall7.init..kmod_tlb__256_1229_create_tlb_single_page_flush_ceiling) ;
		*(.initcall7.init..kmod_memtype__236_1216_pat_memtype_list_init) ;
		*(.initcall7.init..kmod_pkeys__332_199_create_init_pkru_value) ;
		*(.initcall7.init..kmod_panic__259_552_init_oops_id) ;
		*(.initcall7.init..kmod_reboot__323_814_reboot_ksysfs_init) ;
		*(.initcall7.init..kmod_clock__687_243_sched_clock_init_late) ;
		*(.initcall7.init..kmod_qos__429_424_cpu_latency_qos_init) ;
		*(.initcall7.init..kmod_main__313_460_pm_debugfs_init) ;
		*(.initcall7.init..kmod_printk__317_3074_printk_late_init) ;
		*(.initcall7.init..kmod_srcutree__389_1381_init_srcu_module_notifier) ;
		*(.initcall7.init..kmod_swiotlb__285_734_swiotlb_create_debugfs) ;
		*(.initcall7.init..kmod_timekeeping_debug__297_44_tk_debug_sleep_time_init) ;
		*(.initcall7.init..kmod_kprobes__377_2819_debugfs_kprobe_init) ;
		*(.initcall7.init..kmod_taskstats__310_698_taskstats_init) ;
		*(.initcall7.init..kmod_system_keyring__145_188_load_system_certificate_list) ;
		*(.initcall7.init..kmod_memory__472_3921_fault_around_debugfs) ;
		*(.initcall7.init..kmod_swapfile__378_2862_max_swapfiles_check) ;
		*(.initcall7.init..kmod_early_ioremap__232_103_check_early_ioremap_leak) ;
		*(.initcall7.init..kmod_process_keys__296_956_init_root_keyring) ;
		*(.initcall7.init..kmod_integrity__227_222_integrity_fs_init) ;
		*(.initcall7.init..kmod_blk_timeout__290_99_blk_timeout_init) ;
		*(.initcall7.init..kmod_random32__423_632_prandom_init_late) ;
		*(.initcall7.init..kmod_error_inject__255_244_init_error_injection) ;
		*(.initcall7.init..kmod_pci__405_6430_pci_resource_alignment_sysfs_init) ;
		*(.initcall7.init..kmod_pci_sysfs__277_1464_pci_sysfs_init) ;
		*(.initcall7.init..kmod_clk__532_3350_clk_debug_init) ;
		*(.initcall7.init..kmod_dmar__308_2056_dmar_free_unused_resources) ;
		*(.initcall7.init..kmod_core__403_1099_sync_state_resume_initcall) ;
		*(.initcall7.init..kmod_dd__246_335_deferred_probe_initcall) ;
		*(.initcall7.init..kmod_trace__334_293_late_resume_init) ;
		*(.initcall7.init..kmod_netconsole__362_973_init_netconsole) ;
		*(.initcall7.init..kmod_acpi_cpufreq__196_1085_acpi_cpufreq_init) ;
		*(.initcall7.init..kmod_memmap__238_417_firmware_memmap_init) ;
		*(.initcall7.init..kmod_efi__294_1024_register_update_efi_random_seed) ;
		*(.initcall7.init..kmod_reboot__238_77_efi_shutdown_init) ;
		*(.initcall7.init..kmod_earlycon__240_50_efi_earlycon_unmap_fb) ;
		*(.initcall7.init..kmod_tcp_cong__605_252_tcp_congestion_default) ;
		*(.initcall7.init..kmod_ipconfig__579_1623_ip_auto_config) ;
		*(.initcall7.init..kmod_cfg80211__1734_4225_regulatory_init_db) ;
		*(.initcall7.init..kmod_mmconfig_shared__261_718_pci_mmcfg_late_insert_resources) ;
	}
	.initcall7s.init : {
		*(.initcall7s.init..kmod_hibernate__478_1020_software_resume) ;
		*(.initcall7s.init..kmod_trace__391_9107_trace_eval_sync) ;
		*(.initcall7s.init..kmod_trace__398_9686_clear_boot_tracer) ;
		*(.initcall7s.init..kmod_trace__400_9708_tracing_set_default_clock) ;
		*(.initcall7s.init..kmod_logo__101_38_fb_logo_late_init) ;
		*(.initcall7s.init..kmod_clk__482_1299_clk_disable_unused) ;
		*(.initcall7s.init..kmod_last__159_29_alsa_sound_last_init) ;
	}
	.con_initcall.init : {
		*(.con_initcall.init..kmod_vt__277_3516_con_init) ;
		*(.con_initcall.init..kmod_8250__289_693_univ8250_console_init) ;
	}
	.initcallearly.init : {
		*(.initcallearly.init..kmod_core__326_2040_init_hw_perf_events) ;
		*(.initcallearly.init..kmod_init__220_175_init_real_mode) ;
		*(.initcallearly.init..kmod_irq__599_75_trace_init_perf_perm_irq_work_exit) ;
		*(.initcallearly.init..kmod_apic__618_1906_validate_x2apic) ;
		*(.initcallearly.init..kmod_hw_nmi__244_58_register_nmi_cpu_backtrace_handler) ;
		*(.initcallearly.init..kmod_softirq__310_735_spawn_ksoftirqd) ;
		*(.initcallearly.init..kmod_core__896_7691_migration_init) ;
		*(.initcallearly.init..kmod_srcutree__385_1304_srcu_bootup_announce) ;
		*(.initcallearly.init..kmod_tree__639_2844_rcu_spawn_core_kthreads) ;
		*(.initcallearly.init..kmod_tree__697_4310_rcu_spawn_gp_kthread) ;
		*(.initcallearly.init..kmod_tree__711_105_check_cpu_stall_init) ;
		*(.initcallearly.init..kmod_tree__767_842_rcu_sysrq_init) ;
		*(.initcallearly.init..kmod_common__327_42_trace_init_flags_sys_enter) ;
		*(.initcallearly.init..kmod_common__329_66_trace_init_flags_sys_exit) ;
		*(.initcallearly.init..kmod_stop_machine__236_585_cpu_stop_init) ;
		*(.initcallearly.init..kmod_kprobes__360_2524_init_kprobes) ;
		*(.initcallearly.init..kmod_trace_output__587_1399_init_events) ;
		*(.initcallearly.init..kmod_trace_printk__268_389_init_trace_printk) ;
		*(.initcallearly.init..kmod_trace_events__639_3450_event_trace_enable_again) ;
		*(.initcallearly.init..kmod_static_call__172_439_static_call_init) ;
		*(.initcallearly.init..kmod_jump_label__204_762_jump_label_init_module) ;
		*(.initcallearly.init..kmod_vsprintf__583_765_initialize_ptr_random) ;
		*(.initcallearly.init..kmod_efi__290_981_efi_memreserve_root_init) ;
		*(.initcallearly.init..kmod_earlycon__238_41_efi_earlycon_remap_fb) ;
	}
	.initcallrootfs.init : {
		*(.initcallrootfs.init..kmod_initramfs__259_642_populate_rootfs) ;
		*(.initcallrootfs.init..kmod_pci_dma__248_136_pci_iommu_init) ;
	}
}
